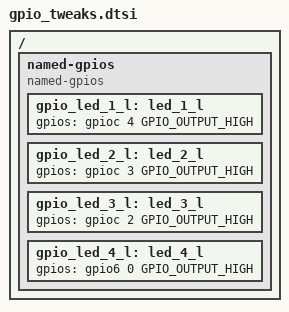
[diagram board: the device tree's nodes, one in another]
/* Copyright 2023 The ChromiumOS Authors
 * Use of this source code is governed by a BSD-style license that can be
 * found in the LICENSE file.
 */

/ {
	named-gpios {
		compatible = "named-gpios";

		/*
		 * Port LEDs start in the off state.
		 * The LED state machine will set them to the desired state.
		 */
		gpio_led_1_l: led_1_l {
			gpios = <&gpioc 4 GPIO_OUTPUT_HIGH>;
		};
		gpio_led_2_l: led_2_l {
			gpios = <&gpioc 3 GPIO_OUTPUT_HIGH>;
		};
		gpio_led_3_l: led_3_l {
			gpios = <&gpioc 2 GPIO_OUTPUT_HIGH>;
		};
		gpio_led_4_l: led_4_l {
			gpios = <&gpio6 0 GPIO_OUTPUT_HIGH>;
		};
	};
};
